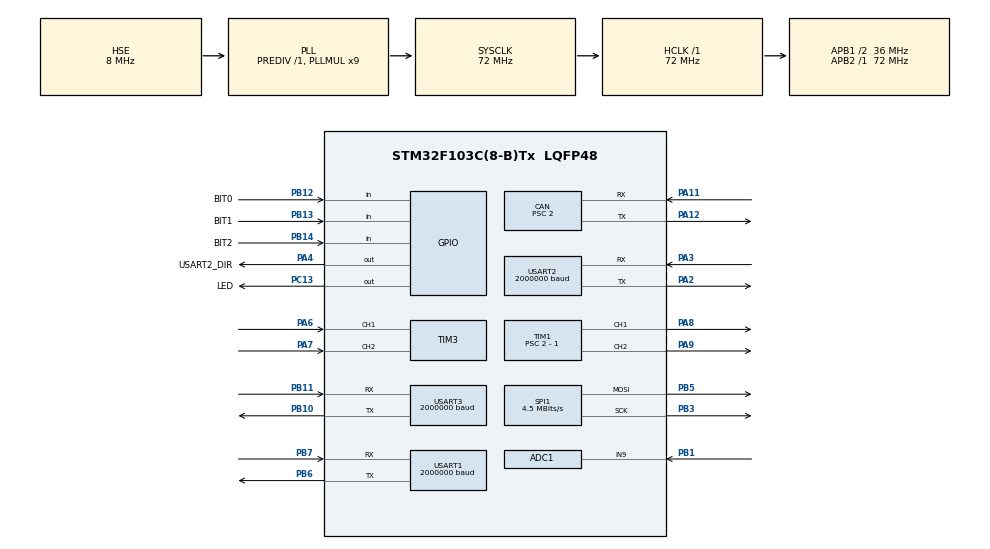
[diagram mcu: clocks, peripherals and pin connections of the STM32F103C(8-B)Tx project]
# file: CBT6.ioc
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ADC1.Channel-0\#ChannelRegularConversion=ADC_CHANNEL_9
ADC1.ContinuousConvMode=ENABLE
ADC1.NbrOfConversionFlag=1
ADC1.Rank-0\#ChannelRegularConversion=1
ADC1.SamplingTime-0\#ChannelRegularConversion=ADC_SAMPLETIME_13CYCLES_5
ADC1.master=1
CAN.BS1=CAN_BS1_9TQ
CAN.BS2=CAN_BS2_8TQ
CAN.CalculateBaudRate=1000000
CAN.CalculateTimeBit=1000
CAN.CalculateTimeQuantum=55.55555555555556
CAN.NART=DISABLE
CAN.Prescaler=2
CAN.TXFP=DISABLE
Dma.ADC1.4.Direction=DMA_PERIPH_TO_MEMORY
Dma.ADC1.4.Instance=DMA1_Channel1
Dma.ADC1.4.MemDataAlignment=DMA_MDATAALIGN_HALFWORD
Dma.ADC1.4.MemInc=DMA_MINC_ENABLE
Dma.ADC1.4.Mode=DMA_CIRCULAR
Dma.ADC1.4.PeriphDataAlignment=DMA_PDATAALIGN_HALFWORD
Dma.ADC1.4.PeriphInc=DMA_PINC_DISABLE
Dma.ADC1.4.Priority=DMA_PRIORITY_LOW
Dma.Request0=USART1_RX
Dma.Request1=USART1_TX
Dma.Request2=USART3_RX
Dma.Request3=USART2_RX
Dma.Request4=ADC1
Dma.USART1_RX.0.Direction=DMA_PERIPH_TO_MEMORY
Dma.USART1_RX.0.Instance=DMA1_Channel5
Dma.USART1_RX.0.MemDataAlignment=DMA_MDATAALIGN_BYTE
Dma.USART1_RX.0.MemInc=DMA_MINC_ENABLE
Dma.USART1_RX.0.Mode=DMA_NORMAL
Dma.USART1_RX.0.PeriphDataAlignment=DMA_PDATAALIGN_BYTE
Dma.USART1_RX.0.PeriphInc=DMA_PINC_DISABLE
Dma.USART1_RX.0.Priority=DMA_PRIORITY_LOW
Dma.USART1_TX.1.Direction=DMA_MEMORY_TO_PERIPH
Dma.USART1_TX.1.Instance=DMA1_Channel4
Dma.USART1_TX.1.MemDataAlignment=DMA_MDATAALIGN_BYTE
Dma.USART1_TX.1.MemInc=DMA_MINC_ENABLE
Dma.USART1_TX.1.Mode=DMA_NORMAL
Dma.USART1_TX.1.PeriphDataAlignment=DMA_PDATAALIGN_BYTE
Dma.USART1_TX.1.PeriphInc=DMA_PINC_DISABLE
Dma.USART1_TX.1.Priority=DMA_PRIORITY_LOW
Dma.USART2_RX.3.Direction=DMA_PERIPH_TO_MEMORY
Dma.USART2_RX.3.Instance=DMA1_Channel6
Dma.USART2_RX.3.MemDataAlignment=DMA_MDATAALIGN_BYTE
Dma.USART2_RX.3.MemInc=DMA_MINC_ENABLE
Dma.USART2_RX.3.Mode=DMA_NORMAL
Dma.USART2_RX.3.PeriphDataAlignment=DMA_PDATAALIGN_BYTE
Dma.USART2_RX.3.PeriphInc=DMA_PINC_DISABLE
Dma.USART2_RX.3.Priority=DMA_PRIORITY_LOW
Dma.USART3_RX.2.Direction=DMA_PERIPH_TO_MEMORY
Dma.USART3_RX.2.Instance=DMA1_Channel3
Dma.USART3_RX.2.MemDataAlignment=DMA_MDATAALIGN_BYTE
Dma.USART3_RX.2.MemInc=DMA_MINC_ENABLE
Dma.USART3_RX.2.Mode=DMA_NORMAL
Dma.USART3_RX.2.PeriphDataAlignment=DMA_PDATAALIGN_BYTE
Dma.USART3_RX.2.PeriphInc=DMA_PINC_DISABLE
Dma.USART3_RX.2.Priority=DMA_PRIORITY_LOW
FREERTOS.Tasks01=defaultTask,24,128,StartDefaultTask,Default,NULL,Dynamic,NULL,NULL;sysTask,40,128,app_sysTask,As external,NULL,Dynamic,NULL,NULL;MotorCtrlTask,24,256,app_motorCtrl,As external,NULL,Dynamic,NULL,NULL;MoterEncTask,8,128,app_encoder,As external,NULL,Dynamic,NULL,NULL;BlockTask,32,128,app_block,As external,NULL,Dynamic,NULL,NULL;StepTask,8,64,app_Step,As external,NULL,Dynamic,NULL,NULL
FREERTOS.configMINIMAL_STACK_SIZE=64
FREERTOS.configTOTAL_HEAP_SIZE=6144
FREERTOS.configUSE_NEWLIB_REENTRANT=1
Mcu.Family=STM32F1
Mcu.Name=STM32F103C(8-B)Tx
Mcu.Package=LQFP48
NVIC.CAN1_RX1_IRQn=true\:5\:0\:false\:false\:true\:true\:true\:true\:true
NVIC.CAN1_SCE_IRQn=true\:5\:0\:false\:false\:true\:true\:true\:true\:true
NVIC.DMA1_Channel1_IRQn=true\:10\:0\:true\:false\:true\:true\:false\:true\:true
NVIC.DMA1_Channel3_IRQn=true\:5\:0\:false\:false\:true\:true\:false\:true\:true
NVIC.DMA1_Channel4_IRQn=true\:5\:0\:false\:false\:true\:true\:false\:true\:true
NVIC.DMA1_Channel5_IRQn=true\:5\:0\:false\:false\:true\:true\:false\:true\:true
NVIC.DMA1_Channel6_IRQn=true\:5\:0\:false\:false\:true\:true\:false\:true\:true
NVIC.PriorityGroup=NVIC_PRIORITYGROUP_4
NVIC.TIM2_IRQn=true\:10\:0\:true\:false\:true\:true\:true\:true\:true
NVIC.TIM4_IRQn=true\:15\:0\:true\:false\:true\:false\:false\:true\:true
NVIC.TimeBase=TIM4_IRQn
NVIC.TimeBaseIP=TIM4
NVIC.USART1_IRQn=true\:5\:0\:true\:false\:true\:true\:false\:true\:true
NVIC.USART2_IRQn=true\:5\:0\:true\:false\:true\:true\:true\:true\:true
NVIC.USART3_IRQn=true\:5\:0\:false\:false\:true\:true\:true\:true\:true
NVIC.USB_HP_CAN1_TX_IRQn=true\:5\:0\:false\:false\:true\:true\:true\:true\:true
NVIC.USB_LP_CAN1_RX0_IRQn=true\:5\:0\:false\:false\:true\:true\:true\:true\:true
PA11.Mode=CAN_Activate
PA11.Signal=CAN_RX
PA12.Mode=CAN_Activate
PA12.Signal=CAN_TX
PA13.Mode=Serial_Wire
PA13.Signal=SYS_JTMS-SWDIO
PA14.Mode=Serial_Wire
PA14.Signal=SYS_JTCK-SWCLK
PA2.Mode=Asynchronous
PA2.Signal=USART2_TX
PA3.Mode=Asynchronous
PA3.Signal=USART2_RX
PA4.GPIO_Label=USART2_DIR
PA4.Signal=GPIO_Output
PA6.Signal=S_TIM3_CH1
PA7.Signal=S_TIM3_CH2
PA8.Signal=S_TIM1_CH1
PA9.Signal=S_TIM1_CH2
PB1.Signal=ADCx_IN9
PB10.Mode=Asynchronous
PB10.Signal=USART3_TX
PB11.Mode=Asynchronous
PB11.Signal=USART3_RX
PB12.GPIO_Label=BIT0
PB12.GPIO_PuPd=GPIO_PULLDOWN
PB12.Signal=GPIO_Input
PB13.GPIO_Label=BIT1
PB13.GPIO_PuPd=GPIO_PULLDOWN
PB13.Signal=GPIO_Input
PB14.GPIO_Label=BIT2
PB14.GPIO_PuPd=GPIO_PULLDOWN
PB14.Signal=GPIO_Input
PB3.Mode=TX_Only_Simplex_Unidirect_Master
PB3.Signal=SPI1_SCK
PB5.Mode=TX_Only_Simplex_Unidirect_Master
PB5.Signal=SPI1_MOSI
PB6.Mode=Asynchronous
PB6.Signal=USART1_TX
PB7.Mode=Asynchronous
PB7.Signal=USART1_RX
PC13-TAMPER-RTC.GPIO_Label=LED
PC13-TAMPER-RTC.Signal=GPIO_Output
PD0-OSC_IN.Mode=HSE-External-Oscillator
PD0-OSC_IN.Signal=RCC_OSC_IN
PD1-OSC_OUT.Mode=HSE-External-Oscillator
PD1-OSC_OUT.Signal=RCC_OSC_OUT
ProjectManager.HeapSize=0x800
ProjectManager.StackSize=0x800
ProjectManager.TargetToolchain=STM32CubeIDE
RCC.ADCPresc=RCC_ADCPCLK2_DIV6
RCC.AHBFreq_Value=72000000
RCC.APB1CLKDivider=RCC_HCLK_DIV2
RCC.APB1Freq_Value=36000000
RCC.APB1TimFreq_Value=72000000
RCC.APB2Freq_Value=72000000
RCC.APB2TimFreq_Value=72000000
RCC.HCLKFreq_Value=72000000
RCC.PLLMUL=RCC_PLL_MUL9
RCC.PLLSourceVirtual=RCC_PLLSOURCE_HSE
RCC.SYSCLKFreq_VALUE=72000000
RCC.SYSCLKSource=RCC_SYSCLKSOURCE_PLLCLK
RCC.USBFreq_Value=72000000
SH.ADCx_IN9.0=ADC1_IN9,IN9
SH.S_TIM1_CH1.0=TIM1_CH1,PWM Generation1 CH1
SH.S_TIM1_CH2.0=TIM1_CH2,PWM Generation2 CH2
SH.S_TIM3_CH1.0=TIM3_CH1,Encoder_Interface
SH.S_TIM3_CH2.0=TIM3_CH2,Encoder_Interface
SPI1.BaudRatePrescaler=SPI_BAUDRATEPRESCALER_16
SPI1.CLKPhase=SPI_PHASE_2EDGE
SPI1.CLKPolarity=SPI_POLARITY_HIGH
SPI1.CalculateBaudRate=4.5 MBits/s
SPI1.Direction=SPI_DIRECTION_2LINES
SPI1.Mode=SPI_MODE_MASTER
SPI1.VirtualType=VM_MASTER
TIM1.Channel-PWM\ Generation1\ CH1=TIM_CHANNEL_1
TIM1.Channel-PWM\ Generation2\ CH2=TIM_CHANNEL_2
TIM1.Period=2250 - 1
TIM1.Prescaler=2 - 1
TIM2.AutoReloadPreload=TIM_AUTORELOAD_PRELOAD_ENABLE
TIM2.Period=500  - 1
TIM2.Prescaler=72 - 1
TIM3.EncoderMode=TIM_ENCODERMODE_TI12
TIM3.IC1Filter=15
TIM3.IC2Filter=15
USART1.BaudRate=2000000
USART1.VirtualMode=VM_ASYNC
USART2.BaudRate=2000000
USART2.VirtualMode=VM_ASYNC
USART3.BaudRate=2000000
USART3.VirtualMode=VM_ASYNC
VP_FREERTOS_VS_CMSIS_V2.Mode=CMSIS_V2
VP_SYS_VS_tim4.Mode=TIM4
VP_TIM1_VS_ClockSourceINT.Mode=Internal
VP_TIM2_VS_ClockSourceINT.Mode=Internal
board=custom

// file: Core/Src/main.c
/* USER CODE BEGIN Header */
/**
  ******************************************************************************
  * @file           : main.c
  * @brief          : Main program body
  ******************************************************************************
  * @attention
  *
  * Copyright (c) 2025 STMicroelectronics.
  * All rights reserved.
  *
  * This software is licensed under terms that can be found in the LICENSE file
  * in the root directory of this software component.
  * If no LICENSE file comes with this software, it is provided AS-IS.
  *
  ******************************************************************************
  */
/* USER CODE END Header */
#include "main.h"
#include "cmsis_os.h"
#include "adc.h"
#include "can.h"
#include "dma.h"
#include "spi.h"
#include "tim.h"
#include "usart.h"
#include "gpio.h"

/* USER CODE BEGIN Includes */
#include "app_motor.h"

/* USER CODE END Includes */

void SystemClock_Config(void);
void MX_FREERTOS_Init(void);

int main(void)
{

  /* MCU Configuration--------------------------------------------------------*/

  /* Reset of all peripherals, Initializes the Flash interface and the Systick. */
  HAL_Init();

  /* Configure the system clock */
  SystemClock_Config();

  /* Initialize all configured peripherals */
  MX_GPIO_Init();
  MX_DMA_Init();
  MX_ADC1_Init();
  MX_TIM1_Init();
  MX_TIM3_Init();
  MX_USART1_UART_Init();
  MX_USART2_UART_Init();
  MX_USART3_UART_Init();
  MX_CAN_Init();
  MX_SPI1_Init();
  MX_TIM2_Init();

  /* Init scheduler */
  osKernelInitialize();

  /* Call init function for freertos objects (in cmsis_os2.c) */
  MX_FREERTOS_Init();

  /* Start scheduler */
  osKernelStart();

  /* We should never get here as control is now taken by the scheduler */

  /* Infinite loop */
  while (1)
  {

  }
}

void SystemClock_Config(void)
{
  RCC_OscInitTypeDef RCC_OscInitStruct = {0};
  RCC_ClkInitTypeDef RCC_ClkInitStruct = {0};
  RCC_PeriphCLKInitTypeDef PeriphClkInit = {0};

  /** Initializes the RCC Oscillators according to the specified parameters
  * in the RCC_OscInitTypeDef structure.
  */
  RCC_OscInitStruct.OscillatorType = RCC_OSCILLATORTYPE_HSE;
  RCC_OscInitStruct.HSEState = RCC_HSE_ON;
  RCC_OscInitStruct.HSEPredivValue = RCC_HSE_PREDIV_DIV1;
  RCC_OscInitStruct.HSIState = RCC_HSI_ON;
  RCC_OscInitStruct.PLL.PLLState = RCC_PLL_ON;
  RCC_OscInitStruct.PLL.PLLSource = RCC_PLLSOURCE_HSE;
  RCC_OscInitStruct.PLL.PLLMUL = RCC_PLL_MUL9;
  if (HAL_RCC_OscConfig(&RCC_OscInitStruct) != HAL_OK)
  {
    Error_Handler();
  }

  /** Initializes the CPU, AHB and APB buses clocks
  */
  RCC_ClkInitStruct.ClockType = RCC_CLOCKTYPE_HCLK|RCC_CLOCKTYPE_SYSCLK
                              |RCC_CLOCKTYPE_PCLK1|RCC_CLOCKTYPE_PCLK2;
  RCC_ClkInitStruct.SYSCLKSource = RCC_SYSCLKSOURCE_PLLCLK;
  RCC_ClkInitStruct.AHBCLKDivider = RCC_SYSCLK_DIV1;
  RCC_ClkInitStruct.APB1CLKDivider = RCC_HCLK_DIV2;
  RCC_ClkInitStruct.APB2CLKDivider = RCC_HCLK_DIV1;

  if (HAL_RCC_ClockConfig(&RCC_ClkInitStruct, FLASH_LATENCY_2) != HAL_OK)
  {
    Error_Handler();
  }
  PeriphClkInit.PeriphClockSelection = RCC_PERIPHCLK_ADC;
  PeriphClkInit.AdcClockSelection = RCC_ADCPCLK2_DIV6;
  if (HAL_RCCEx_PeriphCLKConfig(&PeriphClkInit) != HAL_OK)
  {
    Error_Handler();
  }
}

void HAL_TIM_PeriodElapsedCallback(TIM_HandleTypeDef *htim)
{
  if (htim->Instance == TIM4)
  {
    HAL_IncTick();
  }
  /* USER CODE BEGIN Callback 1 */
  if (htim->Instance == TIM2)
  {
    app_tim_current();
  }

  /* USER CODE END Callback 1 */
}

void Error_Handler(void)
{
  __disable_irq();
  while (1)
  {
  }
}

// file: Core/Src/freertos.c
/* USER CODE BEGIN Header */
/**
  ******************************************************************************
  * File Name          : freertos.c
  * Description        : Code for freertos applications
  ******************************************************************************
  * @attention
  *
  * Copyright (c) 2025 STMicroelectronics.
  * All rights reserved.
  *
  * This software is licensed under terms that can be found in the LICENSE file
  * in the root directory of this software component.
  * If no LICENSE file comes with this software, it is provided AS-IS.
  *
  ******************************************************************************
  */
/* USER CODE END Header */

#include "FreeRTOS.h"
#include "task.h"
#include "main.h"
#include "cmsis_os.h"

/* Definitions for defaultTask */
osThreadId_t defaultTaskHandle;
const osThreadAttr_t defaultTask_attributes = {
  .name = "defaultTask",
  .stack_size = 128 * 4,
  .priority = (osPriority_t) osPriorityNormal,
};
/* Definitions for sysTask */
osThreadId_t sysTaskHandle;
const osThreadAttr_t sysTask_attributes = {
  .name = "sysTask",
  .stack_size = 128 * 4,
  .priority = (osPriority_t) osPriorityHigh,
};
/* Definitions for MotorCtrlTask */
osThreadId_t MotorCtrlTaskHandle;
const osThreadAttr_t MotorCtrlTask_attributes = {
  .name = "MotorCtrlTask",
  .stack_size = 256 * 4,
  .priority = (osPriority_t) osPriorityNormal,
};
/* Definitions for MoterEncTask */
osThreadId_t MoterEncTaskHandle;
const osThreadAttr_t MoterEncTask_attributes = {
  .name = "MoterEncTask",
  .stack_size = 128 * 4,
  .priority = (osPriority_t) osPriorityLow,
};
/* Definitions for BlockTask */
osThreadId_t BlockTaskHandle;
const osThreadAttr_t BlockTask_attributes = {
  .name = "BlockTask",
  .stack_size = 128 * 4,
  .priority = (osPriority_t) osPriorityAboveNormal,
};
/* Definitions for StepTask */
osThreadId_t StepTaskHandle;
const osThreadAttr_t StepTask_attributes = {
  .name = "StepTask",
  .stack_size = 64 * 4,
  .priority = (osPriority_t) osPriorityLow,
};

void StartDefaultTask(void *argument);
extern void app_sysTask(void *argument);
extern void app_motorCtrl(void *argument);
extern void app_encoder(void *argument);
extern void app_block(void *argument);
extern void app_Step(void *argument);

void MX_FREERTOS_Init(void); /* (MISRA C 2004 rule 8.1) */

void MX_FREERTOS_Init(void) {

  /* Create the thread(s) */
  /* creation of defaultTask */
  defaultTaskHandle = osThreadNew(StartDefaultTask, NULL, &defaultTask_attributes);

  /* creation of sysTask */
  sysTaskHandle = osThreadNew(app_sysTask, NULL, &sysTask_attributes);

  /* creation of MotorCtrlTask */
  MotorCtrlTaskHandle = osThreadNew(app_motorCtrl, NULL, &MotorCtrlTask_attributes);

  /* creation of MoterEncTask */
  MoterEncTaskHandle = osThreadNew(app_encoder, NULL, &MoterEncTask_attributes);

  /* creation of BlockTask */
  BlockTaskHandle = osThreadNew(app_block, NULL, &BlockTask_attributes);

  /* creation of StepTask */
  StepTaskHandle = osThreadNew(app_Step, NULL, &StepTask_attributes);

}

void StartDefaultTask(void *argument)
{
  /* USER CODE BEGIN StartDefaultTask */
  /* Infinite loop */
  for(;;)
  {
    osDelay(100);
  }
  /* USER CODE END StartDefaultTask */
}
